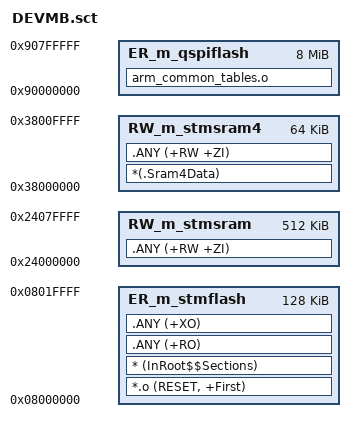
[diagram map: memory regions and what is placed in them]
#! armcc -E 
//////////////////////////////////////////////////////////////////////////////////  
//STM32H750分散加载文件(.scf文件)

#define m_stmflash_start				0X08000000		//m_stmflash(STM32内部FLASH)域起始地址
#define m_stmflash_size					0X20000			//m_stmflash(STM32内部FLASH)大小,H750是128KB

#define m_qspiflash_start				0X90000000		//m_qspiflash(外扩QSPI FLASH)域起始地址
#define m_qspiflash_size				0X800000		//m_qspiflash(外扩QSPI FLASH)大小,W25Q64是8MB
 
#define m_stmsram_start					0X24000000		//m_stmsram(STM32内部RAM)域起始地址,定义在D1,AXI SRAM
#define m_stmsram_size					0X80000			//m_stmsram(STM32内部RAM)大小,AXI SRAM共512KB

#define m_stmsram4_start				0X38000000		//m_stmsram4(STM32内部RAM)域起始地址,定义在D3,AHB SRAM4
#define m_stmsram4_size					0X10000			//m_stmsram4(STM32内部RAM)大小,AHB SRAM4共64KB
  
LR_m_stmflash m_stmflash_start m_stmflash_size {
  ER_m_stmflash m_stmflash_start m_stmflash_size {	
	*.o (RESET, +First)																			
	* (InRoot$$Sections)								
	.ANY (+RO)
	.ANY (+XO)
  } 
  RW_m_stmsram m_stmsram_start m_stmsram_size {	
	.ANY (+RW +ZI)										
  }
  RW_m_stmsram4 m_stmsram4_start m_stmsram4_size {	
	*(.Sram4Data)
	.ANY (+RW +ZI)										
  }
}

LR_m_qspiflash m_qspiflash_start m_qspiflash_size {	
   ER_m_qspiflash m_qspiflash_start m_qspiflash_size {
	arm_common_tables.o
  }															 
}










































